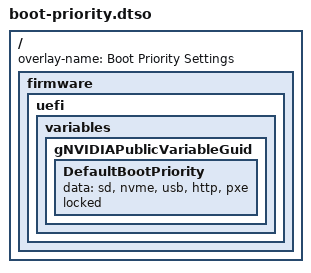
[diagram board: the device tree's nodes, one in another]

/dts-v1/;
/ {
    overlay-name = "Boot Priority Settings";
    fragment@0 {
        target-path = "/";
        board_config { sw-modules = "uefi"; };
        __overlay__ {
            firmware {
                uefi {
                    variables {
                        gNVIDIAPublicVariableGuid {
                            /* Valid tokens include: sd, nvme, usb, emmc, sata, http, pxe, shell */
                            DefaultBootPriority {
                                /* Put SD first, then NVMe, then USB, then HTTP/PXE */
                                data = "sd, nvme, usb, http, pxe";
                                locked;
                            };
                        };
                    };
                };
            };
        };
    };
};
